# pmac_tx_secure register map
Vendor: Texas Instruments
Registers are 32-bit, access per field, reset 0x0 unless marked. A register's access mark holds for its fields unless they carry their own. Offsets are as the file gives them; [hi:lo] are bit positions; lines under a group give offsets from that group; {n}, {i} and the like mark numbered series; <NAME> marks a mode.

## pmac_tx_secure (part 2 of 3)
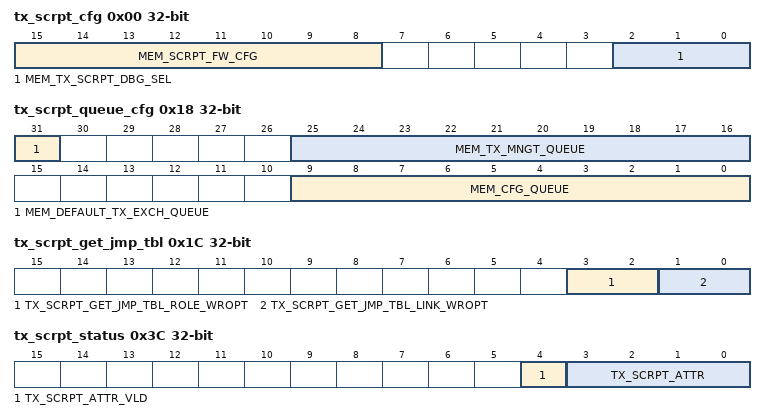
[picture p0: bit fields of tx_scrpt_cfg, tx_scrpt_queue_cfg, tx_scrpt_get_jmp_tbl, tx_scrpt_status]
0x00 tx_scrpt_cfg reset not defined
  [15:8] MEM_SCRPT_FW_CFG rw — general purpose FW config. this field is connected to the scripter hw_indication number 6
  [2:0] MEM_TX_SCRPT_DBG_SEL rw — scripter debug port select. when 0 - debug port is forced to all 0s
0x04 tx_scrpt_va_idx reset not defined
  [8:0] TX_SCRPT_VA_IDX_WROPT rw — Virtual index as popped from a descriptor fifo.
0x08 tx_scrpt_va_offset reset not defined
  [12:0] TX_SCRPT_CURR_VA_OFFSET_WROPT rw — offset inside the descriptor. reset to 0 on every script_start_stb. can be directly written in order to provide larger offsets than what the scripter command offset can allow.
0x0C tx_scrpt_queue_sel
  [2:0] TX_SCRPT_QUEUE_SEL_WROPT rw — Select which fifo base is used for scripter base 0 clears to 0 on every scrpt_start_stb 3'h0 : Main queue - AC group (const and AC index from tx manager 3'h1 : DEST FIFO (cfg via bits 10:8) 3'h2 : VA IDX - to be used in "get_next" fifo command. 3'h3 : Extra queue - AC4 or AC5 (depends on configuration). 3'h4 : Management queue (for Beamforming sequence number managment). 3'h5 : general configurable queue (bits 25:16)
0x10 tx_scrpt_link_addr reset not defined
  [23:0] TX_SCRPT_LNK_ADDR_WROPT rw — full link address
0x14 tx_scrpt_role_addr reset not defined
  [23:0] TX_SCRPT_ROLE_ADDR_WROPT rw — full role address
0x18 tx_scrpt_queue_cfg reset not defined
  [31] MEM_DEFAULT_TX_EXCH_QUEUE rw — 0: rx complete queue 1: tx_exchange queue
  [25:16] MEM_TX_MNGT_QUEUE rw — fifo queue used when the selector is at the configurable fifo option
  [9:0] MEM_CFG_QUEUE rw — fifo queue used when the selector is at the configurable fifo option
0x1C tx_scrpt_get_jmp_tbl reset not defined
  [3:2] TX_SCRPT_GET_JMP_TBL_ROLE_WROPT rw — controls the input to bases 4 and 5 (role) - 2'b00:full role address is used 2'b01:jump table base + role index. 2'b10: use the role_id from the rx interface (used in Imm resp cases to access the role fourn by rx) this field is automatically set to 2'b01if current script scrpt_attr is high at the beginning of the script. it is automatically cleared (2'b00) when writing to the TX_SCRPT_ROLE_ADDR register.
  [1:0] TX_SCRPT_GET_JMP_TBL_LINK_WROPT rw — when set to 1, bases 2 and3 (link) point to their jump table base + link index. when set to 2, jump table base + rx_link index. when set to 0, full link address is used. this bit is automatically set if current script scrpt_attr is high at the begginning of the script. it is automatically cleared when writing to the TX_SCRPT_LINK_ADDR register.
0x20 tx_scrpt_role_ac reset not defined
  [7:0] TX_SCRPT_ROLE_AC_WROPT rw — contains the current script AC. at scrpt_start_stb it samples the relevant AC assigned by the tx_manager. it can be written later to use it to access other ROLE_DB areas.
0x24 tx_scrpt_base_6 reset not defined
  [23:0] MEM_TX_SCRPT_GEN_BASE_6 rw — base 6 root offset. the full base offset is the addition of this field along with TX_SCRPT_BASE_6_GEN_IDX << 2
0x28 tx_scrpt_base_6_gen_idx reset not defined
  [7:0] MEM_TX_SCRPT_BASE_6_GEN_IDX rw — this filed is added to TX_SCRPT_BASE_6 to form a general purpose base config. valud is multiplied by 4 when used.
0x2C tx_scrpt_base_7 reset not defined
  [23:0] MEM_TX_SCRPT_GEN_BASE_7 rw — general purpose offset connected to base7
0x30 tx_scrpt_tmp_mask reset not defined
  [7:0] TX_SCRPT_TMP_MASK_IN_WROPT rw — used by the scripter on single address commands.
0x34 tx_scrpt_tmp_val reset not defined
  [7:0] TX_SCRPT_TMP_VALUE_IN_WROPT rw — used by the scripter on specific commands and on if/jump commands
0x38 tx_scrpt_tmp_lnk reset not defined
  [9:0] TX_SCRPT_TMP_LINK_IN_WROPT rw — used by the LINK command as the return address.
0x3C tx_scrpt_status ro reset not defined
  [4] TX_SCRPT_ATTR_VLD — validator for tx_scrpt_attr field
  [3:0] TX_SCRPT_ATTR — scripter output tx_scrpt_attr. valid only when tx_scrpt_attr_vld is asserted
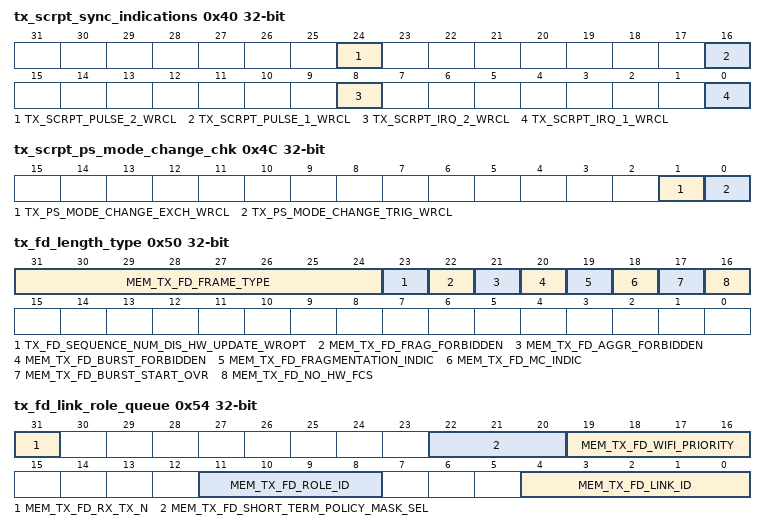
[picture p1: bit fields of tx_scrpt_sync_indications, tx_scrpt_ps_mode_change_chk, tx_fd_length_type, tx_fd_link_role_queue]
0x40 tx_scrpt_sync_indications — writing to one of the 4 bits will create a pulse. TX_SCRPT_IRQ - Connected to interrupt controller to synchronization SW on event coming from scripter. TX_SCRPT_PULSE - Not in use.
  [24] TX_SCRPT_PULSE_2_WRCL wo, [16] TX_SCRPT_PULSE_1_WRCL wo, [8] TX_SCRPT_IRQ_2_WRCL wo, [0] TX_SCRPT_IRQ_1_WRCL wo
0x44 tx_scrpt_nxt_va_idx — used when performing a "get_next_ptr" from the descritor fifo. loads to TX_SCRPT_VA_IDX on aggregatio calculation loop when starting processing of current frame.
  [8:0] MEM_TX_SCRPT_NXT_VA_IDX rw
0x48 tx_scrpt_curr_tx_data_q ro reset not defined
  [15:6] CURR_TX_DATA_Q — Main queue - AC group (const and AC index from tx manager) curr_tx_data_q = {DSCRF_QUEUE_GROUP_PMAC_ACCESS_CATEGORY, 2'b0,tx_scrpt_curr_ac_idx[2:0]} Used in Exchange script to merge temp queue back to main queue.
0x4C tx_scrpt_ps_mode_change_chk
  [1] TX_PS_MODE_CHANGE_EXCH_WRCL wo — When set, if the ps mode has changed due to tx_exchange process, an IRQ will be asserted. the change detection logic is combinatorial. script write to this bit will assert the irq (if change was detected)
  [0] TX_PS_MODE_CHANGE_TRIG_WRCL wo — When set, if the ps mode has changed due to tx_trigger process, an IRQ will be asserted. the change detection logic is combinatorial. script write to this bit will assert the irq (if change was detected)
0x50 tx_fd_length_type
  [31:24] MEM_TX_FD_FRAME_TYPE rw — WLAN frame type from WLAN header.
  [23] TX_FD_SEQUENCE_NUM_DIS_HW_UPDATE_WROPT rw — '1' - sequence number is already allocated. '0' - PMAC should allocate sequence number. this bit may be set by SW, and should be overridden by PMAC when sequence number is allocated (for retry).
  [22] MEM_TX_FD_FRAG_FORBIDDEN rw — SW override for PMAC decision. Current frame can't be fragmented.
  [21] MEM_TX_FD_AGGR_FORBIDDEN rw — SW override for PMAC decision. Current frame wont be part of aggregation.
  [20] MEM_TX_FD_BURST_FORBIDDEN rw — SW override for PMAC decision. Current frame wont be part of burst.
  [19] MEM_TX_FD_FRAGMENTATION_INDIC rw — WLAN Fragmentation indication from WLAN header.
  [18] MEM_TX_FD_MC_INDIC rw — WLAN multicast indication from WLAN header.
  [17] MEM_TX_FD_BURST_START_OVR rw — SW force this frame to start burst
  [16] MEM_TX_FD_NO_HW_FCS rw — when set, HW do not append FCS
0x54 tx_fd_link_role_queue reset not defined
  [31] MEM_TX_FD_RX_TX_N rw — indication of the flow direction of this frame. rx: 1 tx: 0
  [22:20] MEM_TX_FD_SHORT_TERM_POLICY_MASK_SEL rw
  [19:16] MEM_TX_FD_WIFI_PRIORITY rw — TID or special queue type.
  [11:8] MEM_TX_FD_ROLE_ID rw — role ID
  [4:0] MEM_TX_FD_LINK_ID rw — link ID
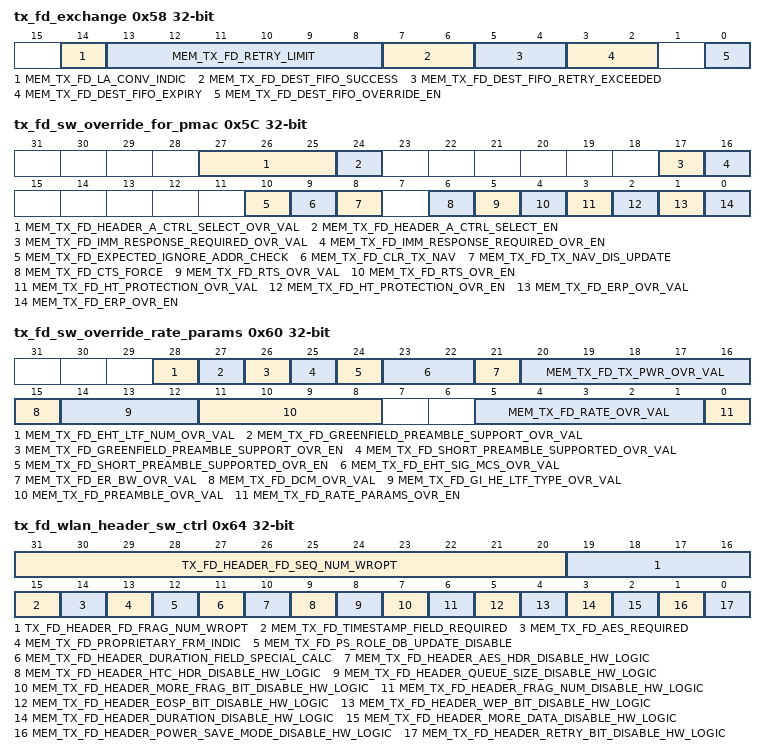
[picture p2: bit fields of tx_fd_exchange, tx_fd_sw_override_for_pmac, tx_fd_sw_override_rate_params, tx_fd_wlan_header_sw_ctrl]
0x58 tx_fd_exchange — destination fifos decoding: 00: de-alloc fifo 01: tx echange complete fifo 10: tx exchange high priority fifo 11: None - dont push to any fifo.
  [14] MEM_TX_FD_LA_CONV_INDIC rw — Set to 1 - frame will be used during the convergence of the link adaptation, frame will be retransmitted until convergence is over. Set to 0 - Otherwise.
  [13:8] MEM_TX_FD_RETRY_LIMIT rw — Retry limit.
  [7:6] MEM_TX_FD_DEST_FIFO_SUCCESS rw — destination fifo in case of success.
  [5:4] MEM_TX_FD_DEST_FIFO_RETRY_EXCEEDED rw — destination fifo in case of retry exceeded.
  [3:2] MEM_TX_FD_DEST_FIFO_EXPIRY rw — destination fifo in case of expiry.
  [0] MEM_TX_FD_DEST_FIFO_OVERRIDE_EN rw — Per frame override - if set go to destination fifo: 01 - tx_exch queue.
0x5C tx_fd_sw_override_for_pmac
  [27:25] MEM_TX_FD_HEADER_A_CTRL_SELECT_OVR_VAL rw — A-Control Type: Set 0 - Operating mode (OM) Set 1 - Buffer status report (BSR) Set 2 - UL power headroom (UPH) Set 3 - Bandwidth query report (BQR) O.W. - SW General Purpose Type.
  [24] MEM_TX_FD_HEADER_A_CTRL_SELECT_EN rw — SW overrides PMAC decision regarding A-Control type selection (in HTC Header).
  [17] MEM_TX_FD_IMM_RESPONSE_REQUIRED_OVR_VAL rw — If override enable bit is set - this bit will set the value - 0 - no imm response is required. 1 - imm response is required.
  [16] MEM_TX_FD_IMM_RESPONSE_REQUIRED_OVR_EN rw — SW override PMAC decision either imm response is required for this frame. (Type & rate of the expected response will be calculated by HW. Only the necessity can be overridden through descriptor).
  [10] MEM_TX_FD_EXPECTED_IGNORE_ADDR_CHECK rw — 1: ignore addr comparison for expected resp checks 0: address comparison is part of expected resp check.
  [9] MEM_TX_FD_CLR_TX_NAV rw — when set, this frame will set the tx_nav to 0. can be used for ps_poll frames and reserved_type/proprietary frames where duration field is not valid
  [8] MEM_TX_FD_TX_NAV_DIS_UPDATE rw — when set, tx_nav will not be updated with the duration field of this frame
  [6] MEM_TX_FD_CTS_FORCE rw — Force CTS protection before frame.
  [5] MEM_TX_FD_RTS_OVR_VAL rw — If overrdie enable bit is set - this bit hold the decison. 1 - Send RTS protection frame. 0 - Dont send RTS protection frame.
  [4] MEM_TX_FD_RTS_OVR_EN rw — SW overrides PMAC decision regardin RTS
  [3] MEM_TX_FD_HT_PROTECTION_OVR_VAL rw — If overrdie enable bit is set - this bit hold the decison. 1 - Send HT protection frame. 0 - Dont send HT protection frame.
  [2] MEM_TX_FD_HT_PROTECTION_OVR_EN rw — SW overrides PMAC decision regardin HT protection
  [1] MEM_TX_FD_ERP_OVR_VAL rw — If overrdie enable bit is set - this bit hold the decison. 1 - Send ERP protection frame. 0 - Dont send ERP protection frame.
  [0] MEM_TX_FD_ERP_OVR_EN rw — SW overrides PMAC decision regardin ERP
0x60 tx_fd_sw_override_rate_params
  [28] MEM_TX_FD_EHT_LTF_NUM_OVR_VAL rw
  [27] MEM_TX_FD_GREENFIELD_PREAMBLE_SUPPORT_OVR_VAL rw — froced value - 0 - mixed mode preamble 1 - greenfield preamble
  [26] MEM_TX_FD_GREENFIELD_PREAMBLE_SUPPORT_OVR_EN rw — Force the use of Greenfield or mixed preamble in case current frame will be transmitted in N rate.
  [25] MEM_TX_FD_SHORT_PREAMBLE_SUPPORTED_OVR_VAL rw — Forced value - 0 - short preamble 1 - long preamble
  [24] MEM_TX_FD_SHORT_PREAMBLE_SUPPORTED_OVR_EN rw — Force the use of short or long preamble in case this frame will be transmitted in B rate.
  [23:22] MEM_TX_FD_EHT_SIG_MCS_OVR_VAL rw
  [21] MEM_TX_FD_ER_BW_OVR_VAL rw — Set 0 - for 242-tone RU Set 1 - for upper frequency 106-tone RU within the primary 20 MHz.
  [20:16] MEM_TX_FD_TX_PWR_OVR_VAL rw — -10 to 20 [dBm]
  [15] MEM_TX_FD_DCM_OVR_VAL rw — Set 1 - dual carrier modulation is used Set 0 - DCM is not used Note: DCM is only applied to MCS0, MCS1, MCS3 and MCS4
  [14:12] MEM_TX_FD_GI_HE_LTF_TYPE_OVR_VAL rw
  [11:8] MEM_TX_FD_PREAMBLE_OVR_VAL rw — Set 0x0 - preamble type B_SHORT Set 0x1 - preamble type B_LONG Set 0x2 - preamble type AG Set 0x3 - preamble type N_MIXED Set 0x4 - preamble type N_GF Set 0x5 - preamble type AX_SU Set 0x6 - preamble type AX_MU Set 0x7 - preamble type AX_SU_ER Set 0x8 - preamble type AX_TB Set 0x9 - preamble type AX_TB_NDP_FB Set 0xA - preamble type AC_VHT
  [5:1] MEM_TX_FD_RATE_OVR_VAL rw — Set 0x1 - rate_1mbps Set 0x2 - rate_2mbps Set 0x3 - rate_5_5mbps Set 0x4 - rate_11mbps Set 0x5 - rate_6mbps Set 0x6 - rate_9mbps Set 0x7 - rate_12mbps Set 0x8 - rate_18mbps Set 0x9 - rate_24mbps Set 0xA - rate_36mbps Set 0xB - rate_48mbps Set 0xC - rate_54mbps Set 0xD - rate_mcs0 (6.5 mbps) Set 0xE - rate_mcs1 (13 mbps) Set 0xF - rate_mcs2 (19.5 mbps) Set 0x10 - rate_mcs3 (26 mbps) Set 0x11 - rate_mcs4 (39 mbps) Set 0x12 - rate_mcs5 (52 mbps) Set 0x13 - rate_mcs6 (58.5 mbps) Set 0x14 - rate_mcs7 (65 mbps)
  [0] MEM_TX_FD_RATE_PARAMS_OVR_EN rw — Use rate parameters (Rate,Preamble,TX Power,GI HE LTF type,DCM) from descriptor override values.
0x64 tx_fd_wlan_header_sw_ctrl rw
  [31:20] TX_FD_HEADER_FD_SEQ_NUM_WROPT — sequence number.
  [19:16] TX_FD_HEADER_FD_FRAG_NUM_WROPT — frag number.
  [15] MEM_TX_FD_TIMESTAMP_FIELD_REQUIRED — Indicate to PMAC that addition of timestamp field is required (will be used for beacon & probe response). The timestamp is added by HW at a fixed location. AES_REQUIRED and 'order bit' fileds should not be set when this bit is set
  [14] MEM_TX_FD_AES_REQUIRED — when set, current frame will be AES encrypted. when clear, current frame wil be transmitted without AES encryption
  [13] MEM_TX_FD_PROPRIETARY_FRM_INDIC — Marks this frame as proprietry frame, the PMAC will treat this frame as raw data, i.e. no WLAN header modifications, header address is a 'don't care' and payload address should point to the start of the raw data. All disables HW logic should be also set to 1.
  [12] MEM_TX_FD_PS_ROLE_DB_UPDATE_DISABLE — If Set to 1 - This frame will not cause PMAC HW to update Power Save state on role DB.
  [11] MEM_TX_FD_HEADER_DURATION_FIELD_SPECIAL_CALC — If set the indicates that initial value in duration field is the end of protected time, and PMAC should calculate according.
  [10] MEM_TX_FD_HEADER_AES_HDR_DISABLE_HW_LOGIC
  [9] MEM_TX_FD_HEADER_HTC_HDR_DISABLE_HW_LOGIC
  [8] MEM_TX_FD_HEADER_QUEUE_SIZE_DISABLE_HW_LOGIC
  [7] MEM_TX_FD_HEADER_MORE_FRAG_BIT_DISABLE_HW_LOGIC
  [6] MEM_TX_FD_HEADER_FRAG_NUM_DISABLE_HW_LOGIC
  [5] MEM_TX_FD_HEADER_EOSP_BIT_DISABLE_HW_LOGIC
  [4] MEM_TX_FD_HEADER_WEP_BIT_DISABLE_HW_LOGIC
  [3] MEM_TX_FD_HEADER_DURATION_DISABLE_HW_LOGIC
  [2] MEM_TX_FD_HEADER_MORE_DATA_DISABLE_HW_LOGIC
  [1] MEM_TX_FD_HEADER_POWER_SAVE_MODE_DISABLE_HW_LOGIC
  [0] MEM_TX_FD_HEADER_RETRY_BIT_DISABLE_HW_LOGIC
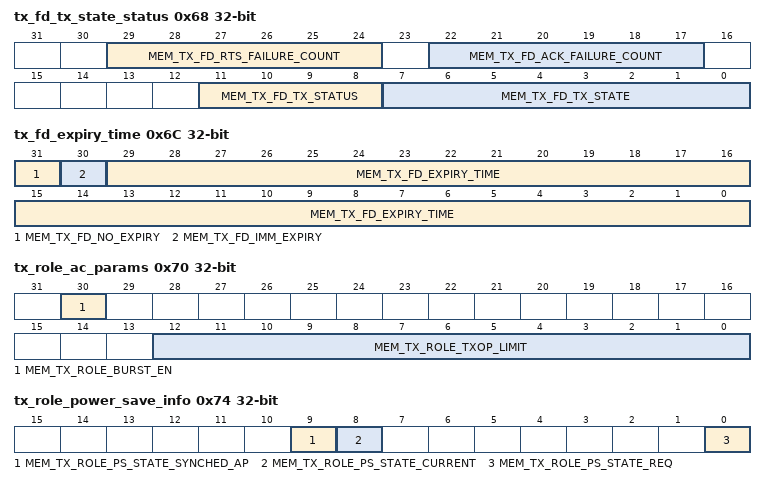
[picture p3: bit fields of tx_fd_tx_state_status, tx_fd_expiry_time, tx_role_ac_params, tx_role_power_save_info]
0x68 tx_fd_tx_state_status
  [29:24] MEM_TX_FD_RTS_FAILURE_COUNT rw
  [22:17] MEM_TX_FD_ACK_FAILURE_COUNT rw
  [11:8] MEM_TX_FD_TX_STATUS rw
  [7:0] MEM_TX_FD_TX_STATE rw — State the NAB should write into the descriptor, once the descriptor is passed to the next stage in the Tx pipeline (TLS).
0x6C tx_fd_expiry_time rw
  [31] MEM_TX_FD_NO_EXPIRY — when set, current frame is not subject to expiry check
  [30] MEM_TX_FD_IMM_EXPIRY — when set, frame is expired immediately after candidate processing.
  [29:0] MEM_TX_FD_EXPIRY_TIME — expiry time in TSF. time is absolute time and not relative to current TSF.
0x70 tx_role_ac_params
  [30] MEM_TX_ROLE_BURST_EN rw, [12:0] MEM_TX_ROLE_TXOP_LIMIT rw
0x74 tx_role_power_save_info
  [9] MEM_TX_ROLE_PS_STATE_SYNCHED_AP rw — the latest power state we are sure the AP is synched to based on expilicit acknowledgements only.
  [8] MEM_TX_ROLE_PS_STATE_CURRENT rw — the state in which the STA is currently at: 1: power save 0: active
  [0] MEM_TX_ROLE_PS_STATE_REQ rw — the power state the station would like to be in. set by SW.
0x78 tx_role_tsf_offset_h rw
  [31:0] MEM_TX_ROLE_TSF_OFFSET_H
0x7C tx_role_tsf_offset_l rw
  [31:0] MEM_TX_ROLE_TSF_OFFSET_L
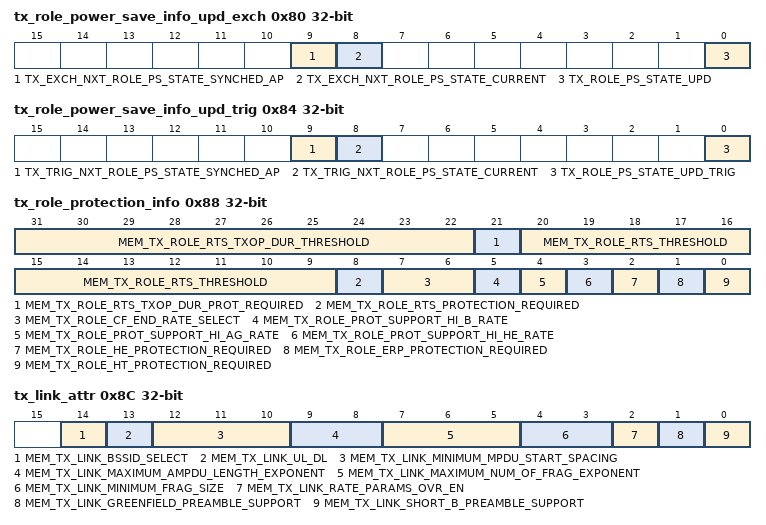
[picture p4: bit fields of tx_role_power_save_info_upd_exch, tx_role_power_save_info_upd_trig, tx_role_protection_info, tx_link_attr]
0x80 tx_role_power_save_info_upd_exch ro
  [9] TX_EXCH_NXT_ROLE_PS_STATE_SYNCHED_AP — the latest power state we are sure the AP is synched to based on expilicit acknowledgements only after current exchange
  [8] TX_EXCH_NXT_ROLE_PS_STATE_CURRENT — the state in which the STA is currently at after current exchange: 1: power save 0: active
  [0] TX_ROLE_PS_STATE_UPD — power state the station would like to be in. set by SW. copied from role DB
0x84 tx_role_power_save_info_upd_trig ro
  [9] TX_TRIG_NXT_ROLE_PS_STATE_SYNCHED_AP — the latest power state we are sure the AP is synched to (no change in trigger)
  [8] TX_TRIG_NXT_ROLE_PS_STATE_CURRENT — the state in which the STA is currently at after current exchange: 1: power save 0: active
  [0] TX_ROLE_PS_STATE_UPD_TRIG — power state the station would like to be in. set by SW. copied from role DB
0x88 tx_role_protection_info rw
  [31:22] MEM_TX_ROLE_RTS_TXOP_DUR_THRESHOLD — PMAC will perform an RTS/CTS exchange when estimated TXOP duration is greater than or equal to 32 us x dot11TXOPDurationRTSThreshold. When SW configure TXOPDurationRTSThreshold coming from AP, it shall subtract worst BA estimation and SIFS duration from the received value. Note that in case dot11TXOPDurationRTSThreshold given by the AP equals 1023, SW will set the RTS_TXOP_DUR_PROT_REQUIRED to zero.
  [21] MEM_TX_ROLE_RTS_TXOP_DUR_PROT_REQUIRED — Role requires RTS protection based on TXOP duration threshold.
  [20:9] MEM_TX_ROLE_RTS_THRESHOLD — Frame length > RTS TH & RTS required will result in RTS protection for the frame.
  [8] MEM_TX_ROLE_RTS_PROTECTION_REQUIRED — Role requires RTS protection based on length TH
  [7:6] MEM_TX_ROLE_CF_END_RATE_SELECT — CF_END rate selection: 00 : CF_end rate is 1MBPS 01 : CF_end rate is 2MBPS 10 : CF_end rate is 6MBPS
  [5] MEM_TX_ROLE_PROT_SUPPORT_HI_B_RATE — if the protcetion frame is using an 11b rate, it may pick the high 11b protection rate out of the possible two.
  [4] MEM_TX_ROLE_PROT_SUPPORT_HI_AG_RATE — if the protcetion frame is using an 11ag rate, it may pick the high 11ag protection rate out of the possible two.
  [3] MEM_TX_ROLE_PROT_SUPPORT_HI_HE_RATE — if the protcetion frame is using an 11ax rate, it may pick the high 11ax protection rate out of the possible two (MCS0 or MCS 3).
  [2] MEM_TX_ROLE_HE_PROTECTION_REQUIRED — Role requires HE protection (for 6GHz Band).
  [1] MEM_TX_ROLE_ERP_PROTECTION_REQUIRED — Role requires ERP protection.
  [0] MEM_TX_ROLE_HT_PROTECTION_REQUIRED — Role requires HT protection.
0x8C tx_link_attr
  [14] MEM_TX_LINK_BSSID_SELECT rw — BSSID set to be used when accessing the rx Immediate response tables.
  [13] MEM_TX_LINK_UL_DL rw — Indicate direction of traffic.
  [12:10] MEM_TX_LINK_MINIMUM_MPDU_START_SPACING rw — Determines the minimum time between the start of adjacent MPDUs within an AMPDU that the peer can receive. May result in additional padding (tail delimiters) after short frames. Set to 0 for no restriction Set to 1 for s Set to 2 for s Set to 3 for 1 s Set to 4 for 2 s Set to 5 for 4 s Set to 6 for 8 s Set to 7 for 16 s
  [9:8] MEM_TX_LINK_MAXIMUM_AMPDU_LENGTH_EXPONENT rw — This field is an integer in the range 0 to 3 used to calc the peer aggregation size limit. The length defined by this field is equal to 2(13 + Maximum A-MPDU Length Exponent) octets.
  [7:5] MEM_TX_LINK_MAXIMUM_NUM_OF_FRAG_EXPONENT rw — Indicates the maximum number of fragmented MSDUs and/or AMSDUs (if supported by the recipient) that the STA is capable of receiving concurrently. The maximum number of fragmented MPDUs - Nmax. Nmax = 2^(Maximum Number Of Fragmented MPDUs) Exponent value 7 indicates that there is no restriction.
  [4:3] MEM_TX_LINK_MINIMUM_FRAG_SIZE rw — Indicates the minimum frame body size in octets of the first fragment of an MPDU that is supported by the recipient STA. Set to 0 to indicate no minimum frame body size. Set to 1 to indicate a minimum frame body size of 128 octets. Set to 2 to indicate a minimum frame body size of 256 octets. Set to 3 to indicate a minimum frame body size of 512 octets.
  [2] MEM_TX_LINK_RATE_PARAMS_OVR_EN rw — Indicates that SW manage rate for this link, therefore rate parameters should come from link DB.
  [1] MEM_TX_LINK_GREENFIELD_PREAMBLE_SUPPORT rw — When using N rates - Greenfield preamble may be used.
  [0] MEM_TX_LINK_SHORT_B_PREAMBLE_SUPPORT rw — When using B rates - short preamble may be used.
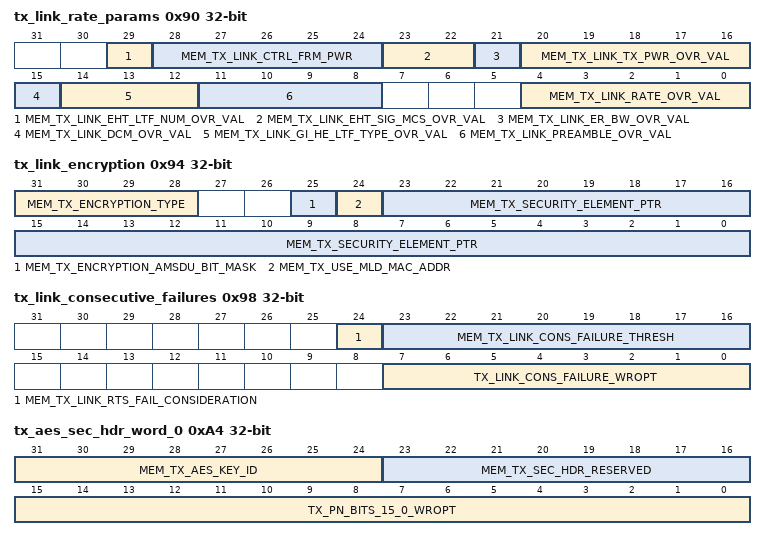
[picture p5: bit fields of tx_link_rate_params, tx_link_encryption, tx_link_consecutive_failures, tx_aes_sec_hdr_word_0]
0x90 tx_link_rate_params — In case rate management will managed by SW - Rate parameters will come from link data base. Parameters include: Rate, Preamble, TX Power, Extened Range Bandwidth, DCM, GI and HE LTF TYPE.
  [29] MEM_TX_LINK_EHT_LTF_NUM_OVR_VAL rw
  [28:24] MEM_TX_LINK_CTRL_FRM_PWR rw — -10 to 20 [dBm]
  [23:22] MEM_TX_LINK_EHT_SIG_MCS_OVR_VAL rw
  [21] MEM_TX_LINK_ER_BW_OVR_VAL rw — Set 0 - for 242-tone RU Set 1 - for upper frequency 106-tone RU within the primary 20 MHz.
  [20:16] MEM_TX_LINK_TX_PWR_OVR_VAL rw — -10 to 20 [dBm]
  [15] MEM_TX_LINK_DCM_OVR_VAL rw — Set 1 - dual carrier modulation is used Set 0 - DCM is not used Note: DCM is only applied to MCS0, MCS1, MCS3 and MCS4
  [14:12] MEM_TX_LINK_GI_HE_LTF_TYPE_OVR_VAL rw
  [11:8] MEM_TX_LINK_PREAMBLE_OVR_VAL rw — Set 0x0 - preamble type B_SHORT Set 0x1 - preamble type B_LONG Set 0x2 - preamble type AG Set 0x3 - preamble type N_MIXED Set 0x4 - preamble type N_GF Set 0x5 - preamble type AX_SU Set 0x6 - preamble type AX_MU Set 0x7 - preamble type AX_SU_ER Set 0x8 - preamble type AX_TB Set 0x9 - preamble type AX_TB_NDP_FB Set 0xA - preamble type AC_VHT
  [4:0] MEM_TX_LINK_RATE_OVR_VAL rw — Set 0x1 - rate_1mbps Set 0x2 - rate_2mbps Set 0x3 - rate_5_5mbps Set 0x4 - rate_11mbps Set 0x5 - rate_6mbps Set 0x6 - rate_9mbps Set 0x7 - rate_12mbps Set 0x8 - rate_18mbps Set 0x9 - rate_24mbps Set 0xA - rate_36mbps Set 0xB - rate_48mbps Set 0xC - rate_54mbps Set 0xD - rate_mcs0 (6.5 mbps) Set 0xE - rate_mcs1 (13 mbps) Set 0xF - rate_mcs2 (19.5 mbps) Set 0x10 - rate_mcs3 (26 mbps) Set 0x11 - rate_mcs4 (39 mbps) Set 0x12 - rate_mcs5 (52 mbps) Set 0x13 - rate_mcs6 (58.5 mbps) Set 0x14 - rate_mcs7 (65 mbps)
0x94 tx_link_encryption
  [31:28] MEM_TX_ENCRYPTION_TYPE rw — Type of encryption. used by PMAC to identify need for AES encryption on the fly.
  [25] MEM_TX_ENCRYPTION_AMSDU_BIT_MASK rw
  [24] MEM_TX_USE_MLD_MAC_ADDR rw — Selector for key addresses
  [23:0] MEM_TX_SECURITY_ELEMENT_PTR rw — Pointer to the structure holding the encryption information.
0x98 tx_link_consecutive_failures
  [24] MEM_TX_LINK_RTS_FAIL_CONSIDERATION rw, [23:16] MEM_TX_LINK_CONS_FAILURE_THRESH rw, [7:0] TX_LINK_CONS_FAILURE_WROPT rw
0x9C tx_link_long_term_policy_mask_lsb rw
  [31:0] MEM_TX_LINK_LONG_TERM_POLICY_MASK_LSB — bit mask of the link supported rates for link adaptation module.
0xA0 tx_link_long_term_policy_mask_msb
  [5:0] MEM_TX_LINK_LONG_TERM_POLICY_MASK_MSB rw — bit mask of the link supported rates for link adaptation module.
0xA4 tx_aes_sec_hdr_word_0 rw — security header 32 lsbs - PN bytes 0 and 1 , reserved byte and key_id byte
  [31:24] MEM_TX_AES_KEY_ID, [23:16] MEM_TX_SEC_HDR_RESERVED, [15:0] TX_PN_BITS_15_0_WROPT
0xA8 tx_aes_sec_hdr_word_1 rw — security header 32 msbs - PN bytes 2,3,4 and 5
  [31:0] TX_PN_BITS_47_16_WROPT
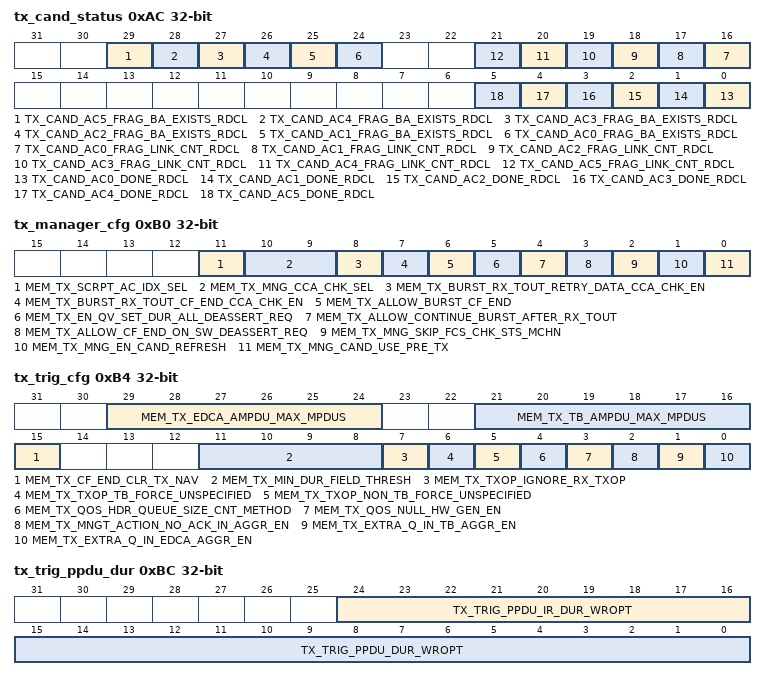
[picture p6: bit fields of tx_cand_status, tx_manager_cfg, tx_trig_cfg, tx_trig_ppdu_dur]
0xAC tx_cand_status ro
  [29] TX_CAND_AC5_FRAG_BA_EXISTS_RDCL — when set, candidate ended with faliure due to only static fragmentation supported and required and BA session is open.
  [28] TX_CAND_AC4_FRAG_BA_EXISTS_RDCL — when set, candidate ended with faliure due to only static fragmentation supported and required and BA session is open.
  [27] TX_CAND_AC3_FRAG_BA_EXISTS_RDCL — when set, candidate ended with faliure due to only static fragmentation supported and required and BA session is open.
  [26] TX_CAND_AC2_FRAG_BA_EXISTS_RDCL — when set, candidate ended with fragmantation request.
  [25] TX_CAND_AC1_FRAG_BA_EXISTS_RDCL — when set, candidate ended with faliure due to only static fragmentation supported and required and BA session is open.
  [24] TX_CAND_AC0_FRAG_BA_EXISTS_RDCL — when set, candidate ended with faliure due to only static fragmentation supported and required and BA session is open.
  [n+16] TX_CAND_AC{n}_FRAG_LINK_CNT_RDCL (n=0..5) — when set, candidate ended with faliure due to reaching maximum frag count in link.
  [n] TX_CAND_AC{n}_DONE_RDCL (n=0..5) — when set, candidate is done. clear on read.
0xB0 tx_manager_cfg reset not defined
  [11] MEM_TX_SCRPT_AC_IDX_SEL rw — AC Selection for scripter - Selected by the active process Set the Priorety of the AC INX selection: '0' - As PG1 , '1' - NEW option for PG2.
  [10:9] MEM_TX_MNG_CCA_CHK_SEL rw — Manager CCA MUX Selector (for checking CCA in case of RX TOUT): Set 00 - Use both PHY_CCA and QUAL_CCA (default). Set 01 - Use Only PHY_CCA. Set 10 - Use Only QUAL_CCA.
  [8] MEM_TX_BURST_RX_TOUT_RETRY_DATA_CCA_CHK_EN rw — Set 1 - After RX Timeout we check CCA before retry transmittion of burst frame. Set 0 - Otherwise.
  [7] MEM_TX_BURST_RX_TOUT_CF_END_CCA_CHK_EN rw — Set 1 - After RX Timeout we check CCA before transmitting CF_END. Set 0 - Otherwise.
  [6] MEM_TX_ALLOW_BURST_CF_END rw — Set 1 - Allow transmission of CF_END at the end of burst. Set 0 - Otherwise.
  [5] MEM_TX_EN_QV_SET_DUR_ALL_DEASSERT_REQ rw — when set, sw may assert qv even if the deassert_all status is not cleared. when cleared (default), sw must read the status before attempting to assert any qv.
  [4] MEM_TX_ALLOW_CONTINUE_BURST_AFTER_RX_TOUT rw
  [3] MEM_TX_ALLOW_CF_END_ON_SW_DEASSERT_REQ rw
  [2] MEM_TX_MNG_SKIP_FCS_CHK_STS_MCHN rw — when set, the tx status machine can ignore the fcs result on ack/cts rx frames if type is as expected. BlockAck frames' fcs is not ignored in any case.
  [1] MEM_TX_MNG_EN_CAND_REFRESH rw — 1:Any rising edge of pre-tx will activate the candidate again. 0: candidate is activated once per transmission.
  [0] MEM_TX_MNG_CAND_USE_PRE_TX rw — 0:manager ac machine starts the candidate immediately when qv is set and a frame exists 1:manager ac machine starts the tx candidate on pre_tx indication (and qv set and frame exists).
0xB4 tx_trig_cfg reset not defined
  [29:24] MEM_TX_EDCA_AMPDU_MAX_MPDUS rw — Maximum number of MPDUs to include in a single EDCA aggregation
  [21:16] MEM_TX_TB_AMPDU_MAX_MPDUS rw — Maximum number of MPDUs to include in a single TB aggregation
  [15] MEM_TX_CF_END_CLR_TX_NAV rw — Set 1 - Clear TX NAV when transmitting CF_END. Set 0 - Don't Clear TX VAN when transmitting CF_END.
  [11:8] MEM_TX_MIN_DUR_FIELD_THRESH rw — threshold duration value for Immediate response HW calculated value. HW calculates the HW generated frame's duration field, if the resulting value is below the threshold, set it to 0 in order to avoid slight errors between the trnamitting and recieving side calculations.
  [7] MEM_TX_TXOP_IGNORE_RX_TXOP rw — When calculating TXOP in TXVECTORS Set 1 - Ignore RX TXOP. Set 0 - O.W.
  [6] MEM_TX_TXOP_TB_FORCE_UNSPECIFIED rw — Set 1 - Force TXOP in TXVECTOR to unspecified value (127) for all HE_TB_PPDUs. Set 0 - O.W.
  [5] MEM_TX_TXOP_NON_TB_FORCE_UNSPECIFIED rw — Set 1 - Force TXOP in TXVECTOR to unspecified value (127) for all PPDUs (excluding HE_TB_PPDU). Set 0 - O.W.
  [4] MEM_TX_QOS_HDR_QUEUE_SIZE_CNT_METHOD rw — Set 0 - Uses queue size counting method described in 11ax amendment - 2 bit - SF, 6 bit - UV. Set 1 - Uses queue size counting method described in 11n/11ac amendments - 8 bit UV (queue size) in 256 byte resolution.
  [3] MEM_TX_QOS_NULL_HW_GEN_EN rw — When transmitting Trigger Based Aggregation, QoS-Null Frames can be aggregated at the end of the transmission (If can fit in reamining TXOP). Set 1 - Enable transmitting HW Generated QoS-Null Frames as part of TB aggregation. Set 0 - Disable transmitting HW Generated QoS-Null Frames as part of TB aggregation.
  [2] MEM_TX_MNGT_ACTION_NO_ACK_IN_AGGR_EN rw — Mngt frames with subtype action No ACK, can be added to QoS-Data aggeregation with less restrictive conditions than 'regular' Mngt frame. Set 1 - Mngt frames with subtype action No ACK can be added with less restrictive conditions. Set 0 - Mngt frames with subtype action No ACK shall be treated as any other Mngt frame.
  [1] MEM_TX_EXTRA_Q_IN_TB_AGGR_EN rw — In Trigger Based Transmission: Set 1 - Enable aggregating single frame (Mngt/Ctrl) from extra queue to a main queue aggregation (QoS-Data). Set 0 - Disable aggregating single frame (Mngt/Ctrl) from extra queue to a main queue aggregation (QoS-Data). Note, This complex aggregation (Mngt/Ctrl + QoS-Data) will be transmitted as part of HE PPDU only.
  [0] MEM_TX_EXTRA_Q_IN_EDCA_AGGR_EN rw — In EDCA Transmission: Set 1 - Enable aggregating single frame (Mngt/Ctrl) from extra queue to a main queue aggregation (QoS-Data). Set 0 - Disable aggregating single frame (Mngt/Ctrl) from extra queue to a main queue aggregation (QoS-Data). Note, This complex aggregation (Mngt/Ctrl + QoS-Data) will be transmitted as part of HE PPDU only.
0xB8 tx_hw_gen_frm_ptr reset not defined — location of HW generated frames for tx - cf_end, ack, ba, multi-sta ba, rts, cts, QoS-null, beamforming report (header only). 32 bit aligned address. Required allocated space is at least 144 bytes - i.e. at least 4 QoS-null frames consecutive.
  [23:2] MEM_TX_HW_GEN_FRM_PTR rw
0xBC tx_trig_ppdu_dur
  [24:16] TX_TRIG_PPDU_IR_DUR_WROPT rw — Transmitted PPDU IR (Immediate Response) duration (micro seconds) as calculated by TX Trigger module.
  [15:0] TX_TRIG_PPDU_DUR_WROPT rw — Transmitted PPDU duration (micro seconds) as calculated by TX Trigger module.
0xC0 tx_queue_seq_num
  [11:0] MEM_TX_QUEUE_SEQ_NUM rw — Main queue sequence number.
0xC4 tx_queue_seq_num_incr ro
  [11:0] TX_QUEUE_SEQ_NUM_FINAL — Main queue final sequence number, to be updated by TX exchange after transmission.
0xC8 tx_max_ppdu_duration reset not defined
  [12:0] MEM_TX_MAX_PPDU_DURATION rw — max ppdu duration in micro seconds
0xCC tx_edca_max_ppdu_length reset not defined — Restirct the maximum allowed PPDU length in EDCA transmission.
  [15:0] MEM_TX_EDCA_MAX_PPDU_LENGTH rw — max ppdu length in bytes
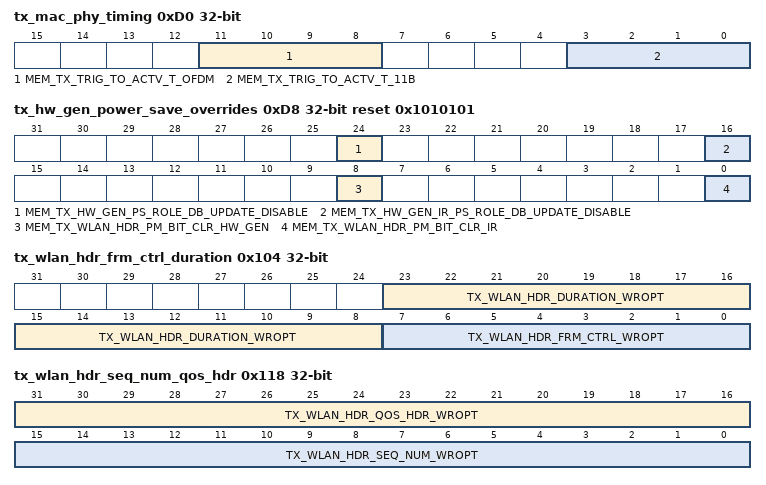
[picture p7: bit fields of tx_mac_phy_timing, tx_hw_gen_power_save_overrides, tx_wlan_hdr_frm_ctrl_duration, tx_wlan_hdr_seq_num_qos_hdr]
0xD0 tx_mac_phy_timing reset not defined
  [11:8] MEM_TX_TRIG_TO_ACTV_T_OFDM rw
  [3:0] MEM_TX_TRIG_TO_ACTV_T_11B rw — time that the phy requires between tx_start (tx_trigger) to tx active. 0.5 usec resolution
0xD4 tx_burst_limits reset not defined
  [8:0] MEM_TX_BURST_DUR_EXTEND_THR rw — time (usec) above the current transaction duration from which a burst can be initiated.
0xD8 tx_hw_gen_power_save_overrides reset 0x1010101
  [24] MEM_TX_HW_GEN_PS_ROLE_DB_UPDATE_DISABLE rw — when set, in HW GEN frames (RTS/CTS-to-self/CF_END) PS role DB will not be updated.
  [16] MEM_TX_HW_GEN_IR_PS_ROLE_DB_UPDATE_DISABLE rw — when set, in Imm Response frames PS role DB will not be updated.
  [8] MEM_TX_WLAN_HDR_PM_BIT_CLR_HW_GEN rw — when set, PM bit in HW generated frames (RTS/CTS-to-self/ CF_END) is zero. when cleared, PS request mode from role DB is used. Note: QoS-null and Beamforming report can't be overriden and PS request mode from role DB will be always used.
  [0] MEM_TX_WLAN_HDR_PM_BIT_CLR_IR rw — when set, PM bit in Imm Response frames is zero. when cleared, PS request mode from role DB is used.
0xDC tx_increment rw
  [31:0] TX_INCREMENT_WROPT — when writing a value to this address, the HW will increment it and only then write. e.g writing 0x1346 to it will result in latching the value 0x1347. when reaching 0xfffffff, counter will wrap to 0x0.
{0xE0+4i} wlan_hdr_wrd{i}_n_aligned rw (i=0..8) — contains the first wlan header word as read from the RAM. word is read with the 2 lsb as zeroes so data may be shifted by up to 3 bytes.
  [31:0] WLAN_HDR_W{i}_N_ALIGNED_WROPT — returns zero.
0x104 tx_wlan_hdr_frm_ctrl_duration — contains the first wlan header word as read from the RAM. word is read with the 2 lsb as zeroes so data may be shifted by up to 3 bytes.
  [23:8] TX_WLAN_HDR_DURATION_WROPT rw, [7:0] TX_WLAN_HDR_FRM_CTRL_WROPT rw
0x108 tx_wlan_hdr_addr_1_msb rw — contains the first wlan header word as read from the RAM. word is read with the 2 lsb as zeroes so data may be shifted by up to 3 bytes.
  [31:0] TX_WLAN_HDR_ADDR_1_MSB_WROPT
0x10C tx_wlan_hdr_addr_1_lsb — contains the first wlan header word as read from the RAM. word is read with the 2 lsb as zeroes so data may be shifted by up to 3 bytes.
  [15:0] TX_WLAN_HDR_ADDR_1_LSB_WROPT rw
0x110 tx_wlan_hdr_addr_2_msb rw — contains the first wlan header word as read from the RAM. word is read with the 2 lsb as zeroes so data may be shifted by up to 3 bytes.
  [31:0] TX_WLAN_HDR_ADDR_2_MSB_WROPT
0x114 tx_wlan_hdr_addr_2_lsb — contains the first wlan header word as read from the RAM. word is read with the 2 lsb as zeroes so data may be shifted by up to 3 bytes.
  [15:0] TX_WLAN_HDR_ADDR_2_LSB_WROPT rw
0x118 tx_wlan_hdr_seq_num_qos_hdr rw — contains the first wlan header word as read from the RAM. word is read with the 2 lsb as zeroes so data may be shifted by up to 3 bytes.
  [31:16] TX_WLAN_HDR_QOS_HDR_WROPT, [15:0] TX_WLAN_HDR_SEQ_NUM_WROPT
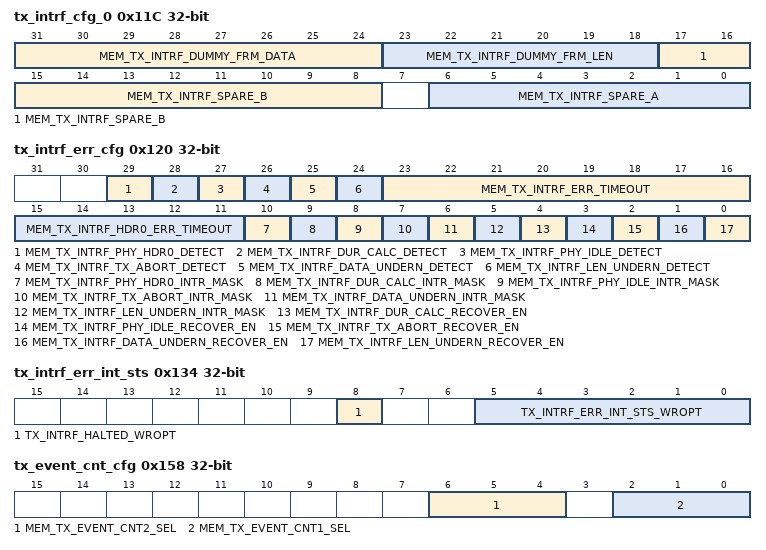
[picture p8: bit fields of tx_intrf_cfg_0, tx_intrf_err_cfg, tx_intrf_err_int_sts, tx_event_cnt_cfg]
0x11C tx_intrf_cfg_0 reset not defined
  [31:24] MEM_TX_INTRF_DUMMY_FRM_DATA rw — in tx error/abort case, payload will be built by repeating this byte.
  [23:18] MEM_TX_INTRF_DUMMY_FRM_LEN rw — tx frame length to be used in the mac-phy interface if the phy read the length before the MAC finished calculating it.
  [17:8] MEM_TX_INTRF_SPARE_B rw — This spare register is maped to Tx header word 2 bits 13-15 for future use purposes.
  [6:0] MEM_TX_INTRF_SPARE_A rw — This spare register is maped to Tx header word 1 bits 24-27 for future use purposes.
0x120 tx_intrf_err_cfg reset not defined — define the tx mac-phy interface error required behavior bitmap: [0]: length not ready [1]: data underflow [2]: tx abort request [3]: too long full fifo (timeout) [4]: invalid duration calculation [5]: header W0 timeout
  [29] MEM_TX_INTRF_PHY_HDR0_DETECT rw — when a bit is set, detect the error when cleared, ignore error - no interrupt, no recover/halt.
  [28] MEM_TX_INTRF_DUR_CALC_DETECT rw — when a bit is set, detect the error when cleared, ignore error - no interrupt, no recover/halt.
  [27] MEM_TX_INTRF_PHY_IDLE_DETECT rw — when a bit is set, detect the error when cleared, ignore error - no interrupt, no recover/halt.
  [26] MEM_TX_INTRF_TX_ABORT_DETECT rw — when a bit is set, detect the error when cleared, ignore error - no interrupt, no recover/halt.
  [25] MEM_TX_INTRF_DATA_UNDERN_DETECT rw — when a bit is set, detect the error when cleared, ignore error - no interrupt, no recover/halt.
  [24] MEM_TX_INTRF_LEN_UNDERN_DETECT rw — when a bit is set, detect the error when cleared, ignore error - no interrupt, no recover/halt.
  [23:16] MEM_TX_INTRF_ERR_TIMEOUT rw — timeout between consecutive phy read transactions (usec). if this timeout is set, interrupt and recovery may me initiated.
  [15:11] MEM_TX_INTRF_HDR0_ERR_TIMEOUT rw — timeout of header word 0 phy read transactions (usec). if this timeout is set, interrupt may me initiated. No recovery for this timeout. To disable this option - set value to 0
  [10] MEM_TX_INTRF_PHY_HDR0_INTR_MASK rw — when a bit is set, mask the interrupt
  [9] MEM_TX_INTRF_DUR_CALC_INTR_MASK rw — when a bit is set, mask the interrupt
  [8] MEM_TX_INTRF_PHY_IDLE_INTR_MASK rw — when a bit is set, mask the interrupt
  [7] MEM_TX_INTRF_TX_ABORT_INTR_MASK rw — when a bit is set, mask the interrupt
  [6] MEM_TX_INTRF_DATA_UNDERN_INTR_MASK rw — when a bit is set, mask the interrupt
  [5] MEM_TX_INTRF_LEN_UNDERN_INTR_MASK rw — when a bit is set, mask the interrupt
  [4] MEM_TX_INTRF_DUR_CALC_RECOVER_EN rw — when a bit is set, implement recovery process when cleared, force 'fifo full' to halt tx and debug.
  [3] MEM_TX_INTRF_PHY_IDLE_RECOVER_EN rw — when a bit is set, implement recovery process when cleared, force 'fifo full' to halt tx and debug.
  [2] MEM_TX_INTRF_TX_ABORT_RECOVER_EN rw — when a bit is set, implement recovery process when cleared, force 'fifo full' to halt tx and debug.
  [1] MEM_TX_INTRF_DATA_UNDERN_RECOVER_EN rw — when a bit is set, implement recovery process when cleared, force 'fifo full' to halt tx and debug.
  [0] MEM_TX_INTRF_LEN_UNDERN_RECOVER_EN rw — when a bit is set, implement recovery process when cleared, force 'fifo full' to halt tx and debug.
0x124 tx_intrf_abort reset not defined
  [0] TX_INTRF_ABORT_WROPT wo — asserting this bit will flush current ongoing tx (not latching - if in idle state, bit is ignored). tx interface fifo will indicate 'empty' status to the MAC allowing flushing the frame as fast as possible. phy will start receiving a constant default data. self clearing.
0x128 tx_burst_tsf_latest_end rw
  [31:0] TX_BURST_TSF_LATEST_END_WROPT — Set by TX Trigger when starting a burst. Indicates burst tsf latest end.
0x12C tx_beacon_timestamp_l ro
  [31:0] TX_BEACON_TIMESTAMP_L — the field contains the 32 lsb of the timestamp to be placed in the beacon and probe reponse timestamp field.
0x130 tx_beacon_timestamp_h ro
  [31:0] TX_BEACON_TIMESTAMP_H — the field contains the 32 lsb of the timestamp to be placed in the beacon and probe reponse timestamp field.
0x134 tx_intrf_err_int_sts reset not defined — define the tx mac-phy interface error required behavior bitmap: [0]: length not ready [1]: data underflow [2]: tx abort request [3]: too long full fifo (timeout) [4]: overflow [5]: header W0 timeout
  [8] TX_INTRF_HALTED_WROPT rw — when set, tx interface had and error and was halted as a result of the error recovery options.
  [5:0] TX_INTRF_ERR_INT_STS_WROPT rw — latches the non-masked interrupt pulses. write 0 to clear. write 1 to set. setting bits by OCP will not assert a new interrupt.
{0x138+4i} tx_hw_gen_frm_{i} ro (i=0..7)
0x158 tx_event_cnt_cfg
  [6:4] MEM_TX_EVENT_CNT2_SEL rw — 3'd0 : reset counter. 3'd1 : counts tx_intrf_irq 3'd2 : counts all intr error events.
  [2:0] MEM_TX_EVENT_CNT1_SEL rw — 3'd0 : reset counter. 3'd1 : counts tx_intrf_irq 3'd2 : counts all intr error events.
0x15C tx_event_cnt1 ro — 32 bit counter of tx events. read only counter. doesnt not clear on read/write.
  [31:0] TX_EVENT_CNT1 — counter value
0x160 tx_event_cnt2 ro — 16 bit counter of tx events. read only counter. doesnt not clear on read/write.
  [15:0] TX_EVENT_CNT2 — counter value
